# AE822FA0E5597BS0_CM55_HP_View register map
Vendor: Alif Semiconductor; Series: E8; File version: 1.0
CPU: CM55 r1p0, selectable endian, MPU, FPU, double-precision FPU, DSP, VTOR, 8 interrupt priority bits, 1 SAU regions
Registers are 32-bit, read-write, reset 0x0 unless marked. A register's access mark holds for its fields unless they carry their own. Offsets are from the block's base; [hi:lo] are bit positions; {n}, {i} and the like mark numbered series; 'fields as' and 'values as' point back to an identical list.

## OSPI0
Base 0x83000000
Same registers: OSPI1 0x83002000
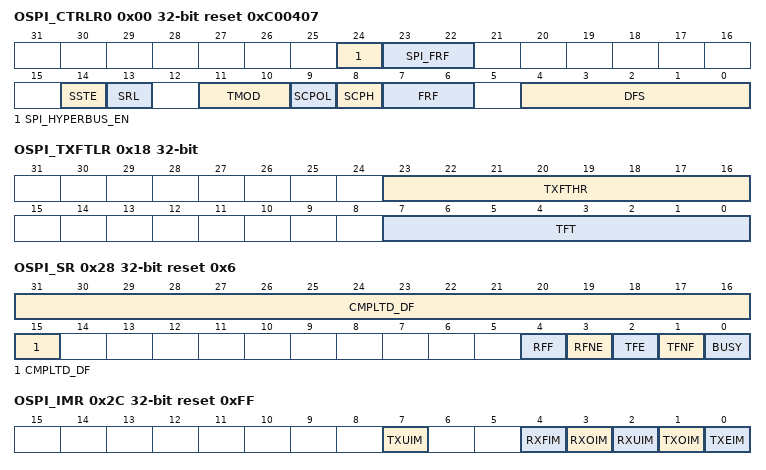
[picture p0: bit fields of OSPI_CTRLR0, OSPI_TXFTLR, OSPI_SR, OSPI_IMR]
0x00 OSPI_CTRLR0 reset 0xC00407 — OSPI Control Register 0
  [24] SPI_HYPERBUS_EN — SPI HyperBus Frame Format Enable. Selects if data frame format for Transmitting/Receiving data is in HyperBus mode.
    0=Disable HyperBus format; 1=Enable HyperBus format
  [23:22] SPI_FRF — SPI Frame Format Selects data frame format for Transmitting/Receiving the data.
    0=Standard SPI format; 1=Dual SPI format; 2=Quad SPI format; 3=Octal SPI format
  [14] SSTE — Slave Select Toggle Enable. While operating in SPI mode with SCPH set to 0, this bit controls the behavior of the slave select line between data frames.
    0=The slave select line will stay low and OSPI_SCLK will run continuously for the duration of the transfer; 1=The slave select line will toggle between consecutive data frames, with the serial clock (OSPI_SCLK) being held to its default value while the slave select line is high
  [13] SRL — Shift Register Loop. Used for testing purposes only. When internally active, connects the transmit shift register output to the receive shift register input.
    0=Normal mode operation; 1=Test mode operation
  [11:10] TMOD — Transfer Mode. Selects the mode of transfer for serial communication. This field does not affect the transfer duplicity. Only indicates whether the receive or transmit data are valid. In Transmit Only mode, data received from the external device is not valid and is not stored in the receive FIFO memory; it is overwritten on the next transfer. In Receive Only mode, transmitted data are not valid. After the first write to the transmit FIFO, the same word is retransmitted for the duration of the transfer. In transmit-and-receive mode, both transmit and receive data are valid. The transfer continues until the transmit FIFO is empty. Data received from the external device are stored into the receive FIFO memory, where it can be accessed by the host processor.
    0=Transmit and Receive; Not Applicable in enhanced SPI operating mode; 1=Transmit Only mode; Or Write in enhanced SPI operating mode; 2=Receive Only mode; Or Read in enhanced SPI operating mode; 3=EEPROM Read mode; Not Applicable in enhanced SPI operating mode
  [9] SCPOL — Serial Clock Polarity. Used to select the polarity of the inactive serial clock, which is held inactive when the OSPI master is not actively transferring data on the serial bus.
    0=Inactive state of serial clock is low; 1=Inactive state of serial clock is high
  [8] SCPH — Serial Clock Phase. The serial clock phase selects the relationship of the serial clock with the slave select signal. When SCPH = 0, data are captured on the first edge of the serial clock. When SCPH = 1, the serial clock starts toggling one cycle after the slave select line is activated, and data are captured on the second edge of the serial clock.
    0=Serial clock toggles in middle of first bit; 1=Serial clock toggles at start of first bit
  [7:6] FRF — Frame Format. Selects which serial protocol transfers the data.
    0=Motorola SPI Frame Format
  [4:0] DFS — Data Frame Size. Selects the data frame length. When the data frame size is programmed to be less than 32-bits, the receive data is automatically right-justified by the receive logic, with the upper bits of the receive FIFO zero-padded. Software must right-justify transmit data before writing into the transmit FIFO. The transmit logic ignores the upper unused bits when transmitting the data. Note: The DFS value must be multiple of 2 if SPI_FRF = 0x1, multiple of 4 if SPI_FRF = 0x2, and multiple of 8 if SPI_FRF = 0x3.
    {v}={v+1:02}-bit serial data transfer (v=3..31)
0x04 OSPI_CTRLR1 — OSPI Control Register 1
  [15:0] NDF — Number of Data Frames. When OSPI_CTRLR0[TMOD] = 0x2 or 0x3, this bit field sets the number of data frames to be continuously received by the OSPI. The OSPI continues to receive serial data until the number of data frames received is equal to this register value plus 1, which enables to receive up to 256KB of data in a continuous transfer. When OSPI_CTRLR0[TMOD] = 0x1, this bit field sets the number of data frames to be continuously transmitted by OSPI. If the Transmit FIFO goes empty in-between, OSPI masks the serial clock (OSPI_SCLK) and waits for rest of the data until the programmed amount of frames are transferred successfully.
0x08 OSPI_ENR — OSPI Enable Register
  [0] OSPI_EN — OSPI Enable. Enables or disables all OSPI operations. When disabled, all serial transfers are halted immediately. Transmit and receive FIFO buffers are cleared when the device is disabled. It is impossible to program some of the OSPI control registers when enabled.
    0=Disables OSPI; 1=Enables OSPI
0x10 OSPI_SER — OSPI Slave Enable Register
  [1:0] SER — Slave Select Enable Flag. Each bit of this bit field corresponds to the slave select line from the OSPI master. When a bit in this bit field is set (0x1), the slave select line from the master is activated when a serial transfer begins. It should be noted that setting or clearing bits in this bit field have no effect on the corresponding slave select output until a transfer is started. Before beginning a transfer, the respective bit in this bit field should be enabled depending which slave select line is desired.
    0=Not selected; 1=Selected
0x14 OSPI_BAUDR reset 0x2 — OSPI Baud Rate Select Register
  [15:1] SCKDV — OSPI Clock Divider. This field contains the MSB 15 bits of the 16-bit SPI_CLK divider value. The LSB for this bit field is always set to 0 and is unaffected by a write operation, which ensures the divider is always set to an even value. If this field is set to all 0s, the serial output clock (OSPI_SCLK) is disabled. The frequency of the OSPI_SCLK is derived from the following equation: FOSPI_SCLK = FOSPI_CLK/BAUDR Where BAUDR is any even value between 2 and 65534, and BAUDR = SCKDV x 2. For example, for FOSPI_CLK = 3.6864 MHz and SCKDV = 1b'1: BAUDR = 2 and FOSPI_SCLK = 3.6864/2 = 1.8432 MHz
0x18 OSPI_TXFTLR — OSPI Transmit FIFO Threshold Level Register
  [23:16] TXFTHR — Transfer Start FIFO Level. Used to control the level of entries in transmit FIFO above which transfer will start on serial line. This bit field is used to ensure that sufficient data is present in transmit FIFO before starting a write operation on serial line.
  [7:0] TFT — Transmit FIFO Threshold. Controls the level of entries (or below) at which the transmit FIFO controller triggers an interrupt. The FIFO depth is 256. If the value in this bit field is greater than or equal to the depth of the FIFO, this bit field is not written and retains its current value. When the number of transmit FIFO entries is less than or equal to this value, the transmit FIFO empty interrupt is triggered.
0x1C OSPI_RXFTLR — OSPI Receive FIFO Threshold Level Register
  [7:0] RFT — Receive FIFO Threshold. Controls the level of entries (or above) at which the receive FIFO controller triggers an interrupt. The FIFO depth is 256. If the value in this bit field is greater than the depth of the FIFO, this bit field is not written and retains its current value. When the number of receive FIFO entries is greater than or equal to this value + 1, the receive FIFO full interrupt is triggered.
0x20 OSPI_TXFLR ro — OSPI Transmit FIFO Level Register
  [8:0] TXTFL — Transmit FIFO Level. Contains the number of valid data entries in the transmit FIFO.
0x24 OSPI_RXFLR ro — OSPI Receive FIFO Level Register
  [8:0] RXTFL — Receive FIFO Level. Contains the number of valid data entries in the receive FIFO.
0x28 OSPI_SR ro reset 0x6 — OSPI Status Register
  [31:15] CMPLTD_DF — Completed Data Frames. This bit field indicates total data frames transferred in the previous internal DMA transfer.
  [4] RFF — Receive FIFO Full. When the receive FIFO is completely full, this bit is set. When the receive FIFO contains one or more empty location, this bit is cleared.
    0=Receive FIFO is not full; 1=Receive FIFO is full
  [3] RFNE — Receive FIFO Not Empty. Set when the receive FIFO contains one or more entries and is cleared when the receive FIFO is empty. This bit can be polled by software to completely empty the receive FIFO.
    0=Receive FIFO is empty; 1=Receive FIFO is not empty
  [2] TFE — Transmit FIFO Empty. When the transmit FIFO is completely empty, this bit is set. When the transmit FIFO contains one or more valid entries, this bit is cleared. This bit field does not request an interrupt.
    0=Transmit FIFO is not empty; 1=Transmit FIFO is empty
  [1] TFNF — Transmit FIFO Not Full. Set when the transmit FIFO contains one or more empty locations, and is cleared when the FIFO is full.
    0=Transmit FIFO is full; 1=Transmit FIFO is not full
  [0] BUSY — OSPI Busy Flag. When set, indicates that a serial transfer is in progress; when cleared indicates that the OSPI is idle or disabled.
    0=OSPI is idle or disabled; 1=OSPI is actively transferring data
0x2C OSPI_IMR reset 0xFF — OSPI Interrupt Mask Register
  [7] TXUIM — Transmit FIFO Underflow Interrupt Mask
    0=Transmit FIFO Underflow interrupt is masked; 1=Transmit FIFO Underflow interrupt is not masked
  [4] RXFIM — Receive FIFO Full Interrupt Mask
    0=Receive FIFO Full interrupt is masked; 1=Receive FIFO Full interrupt is not masked
  [3] RXOIM — Receive FIFO Overflow Interrupt Mask
    0=Receive FIFO Overflow interrupt is masked; 1=Receive FIFO Overflow interrupt is not masked
  [2] RXUIM — Receive FIFO Underflow Interrupt Mask
    0=Receive FIFO Underflow interrupt is masked; 1=Receive FIFO Underflow interrupt is not masked
  [1] TXOIM — Transmit FIFO Overflow Interrupt Mask
    0=Transmit FIFO Overflow interrupt is masked; 1=Transmit FIFO Overflow interrupt is not masked
  [0] TXEIM — Transmit FIFO Empty Interrupt Mask
    0=Transmit FIFO Empty interrupt is masked; 1=Transmit FIFO Empty interrupt is not masked
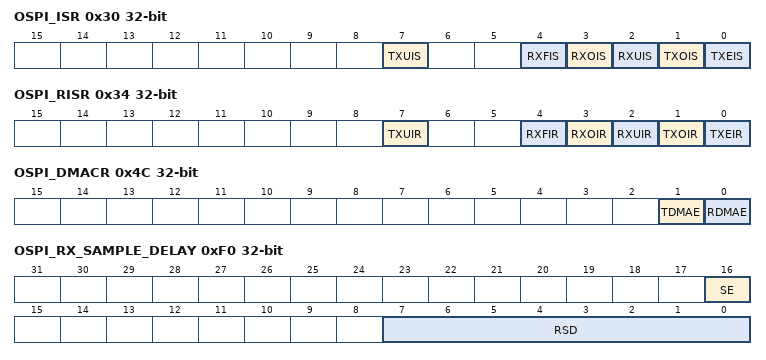
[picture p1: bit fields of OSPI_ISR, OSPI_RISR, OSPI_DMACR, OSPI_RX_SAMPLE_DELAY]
0x30 OSPI_ISR ro — OSPI Interrupt Status Register
  [7] TXUIS — Transmit FIFO Underflow Interrupt Status
    0=Transmit FIFO Underflow interrupt is not active after masking; 1=Transmit FIFO Underflow interrupt is active after masking
  [4] RXFIS — Receive FIFO Full Interrupt Status.
    0=Receive FIFO Full interrupt is not active after masking; 1=Receive FIFO Full interrupt is active after masking
  [3] RXOIS — Receive FIFO Overflow Interrupt Status.
    0=Receive FIFO Overflow interrupt is not active after masking; 1=Receive FIFO Overflow interrupt is active after masking
  [2] RXUIS — Receive FIFO Underflow Interrupt Status.
    0=Receive FIFO Underflow interrupt is not active after masking; 1=Receive FIFO Underflow interrupt is active after masking
  [1] TXOIS — Transmit FIFO Overflow Interrupt Status.
    0=Transmit FIFO Overflow interrupt is not active after masking; 1=Transmit FIFO Overflow interrupt is active after masking
  [0] TXEIS — Transmit FIFO Empty Interrupt Status.
    0=Transmit FIFO Empty interrupt is not active after masking; 1=Transmit FIFO Empty interrupt is active after masking
0x34 OSPI_RISR ro — OSPI Raw Interrupt Status Register
  [7] TXUIR — Transmit FIFO Underflow Interrupt Raw Status
    0=Transmit FIFO Underflow interrupt is not active prior masking; 1=Transmit FIFO Underflow interrupt is active prior to masking
  [4] RXFIR — Receive FIFO Full Raw Interrupt Status.
    0=Receive FIFO Full interrupt is not active prior masking; 1=Receive FIFO Full interrupt is active prior to masking
  [3] RXOIR — Receive FIFO Overflow Raw Interrupt Status.
    0=Receive FIFO Overflow interrupt is not active prior masking; 1=Receive FIFO Overflow interrupt is active prior to masking
  [2] RXUIR — Receive FIFO Underflow Raw Interrupt Status.
    0=Receive FIFO Underflow interrupt is not active prior masking; 1=Receive FIFO Underflow interrupt is active prior to masking
  [1] TXOIR — Transmit FIFO Overflow Raw Interrupt Status.
    0=Transmit FIFO Overflow interrupt is not active prior masking; 1=Transmit FIFO Overflow interrupt is active prior to masking
  [0] TXEIR — Transmit FIFO Empty Raw Interrupt Status.
    0=Transmit FIFO Empty interrupt is not active prior masking; 1=Transmit FIFO Empty interrupt is active prior to masking
0x38 OSPI_TXEICR ro — OSPI Transmit FIFO Error Interrupt Clear Register
  [0] TXEICR — Clear Transmit FIFO Overflow/Underflow Interrupt. This bit reflects the status of the interrupt. A read from this bit clears the Transmit FIFO Overflow/Underflow interrupt; writing has no effect.
0x3C OSPI_RXOICR ro — OSPI Receive FIFO Overflow Interrupt Clear Register
  [0] RXOICR — Clear Receive FIFO Overflow Interrupt. This bit reflects the status of the interrupt. A read from this bit clears the Receive FIFO Overflow interrupt; writing has no effect.
0x40 OSPI_RXUICR ro — OSPI Receive FIFO Underflow Interrupt Clear Register
  [0] RXUICR — Clear Receive FIFO Underflow Interrupt. This bit reflects the status of the interrupt. A read from this bit clears the Receive FIFO Underflow interrupt; writing has no effect.
0x48 OSPI_ICR ro — OSPI Interrupt Clear Register
  [0] ICR — Clear Interrupts. This bit is set if any of the interrupts below are active. A read clears the Transmit FIFO Underflow, Transmit FIFO Overflow, Receive FIFO Underflow, and Receive FIFO Overflow interrupts. Writing to this bit has no effect.
0x4C OSPI_DMACR — OSPI DMA Control Register
  [1] TDMAE — Transmit DMA Enable. This bit enables/disables the transmit FIFO DMA channel.
    0=Transmit DMA disabled; 1=Transmit DMA enabled
  [0] RDMAE — Receive DMA Enable. This bit enables/disables the receive FIFO DMA channel.
    0=Receive DMA disabled; 1=Receive DMA enabled
0x50 OSPI_DMATDLR — OSPI DMA Transmit Data Level Register
  [7:0] DMATDL — Transmit Data Level. This bit field controls the level at which a DMA request is made by the transmit logic. It is equal to the Watermark Level; that is, the OSPI_DMA_TX_REQ signal is generated when the number of valid data entries in the transmit FIFO is equal to or below this field value, and OSPI_DMACR[TDMAE] = 1.
0x54 OSPI_DMARDLR — OSPI DMA Receive Data Level Register
  [7:0] DMARDL — Receive Data Level. This bit field controls the level at which a DMA request is made by the receive logic. The Watermark Level is equal to OSPI_DMARDLR[DMARDL] + 1; that is, OSPI_DMA_RX_REQ is generated when the number of valid data entries in the receive FIFO is equal to or above this field value + 1, and OSPI_DMACR[RDMAE] = 1.
0x58 OSPI_IDR ro reset 0xC7C5C7C5 — Identification Register
  [31:0] IDCODE — Identification code
0x5C OSPI_VERSION_ID ro reset 0x3230312A — Version ID Register
  [31:0] OSPI_COMP_VERSION — Component version
{0x60+4i} OSPI_DR[{i}] (i=0..35) — OSPI Data Register (n)
  [31:0] DR — Data Register (n). When writing to this register, the data must be right-justified. Read data are automatically right-justified. Read = Receive FIFO buffer Write = Transmit FIFO buffer
0xF0 OSPI_RX_SAMPLE_DELAY
  [16] SE — RXD Sampling Edge. This bit is used to decide the sampling edge for RXD signal with OSPI_CLK. Then this bit is set to 1 then negative edge of OSPI_CLK will be used to sample the incoming data, otherwise positive edge will be used for sampling.
  [7:0] RSD — RXD Sample Delay. This bit field is used to delay the sample of the RXD input port. Each value represents a single OSPI_CLK delay on the sample of RXD. Note: If this bit is programmed with a value that exceeds the depth of the internal shift registers (internal shift register depth = 8) zero delay will be applied to the RXD sample.
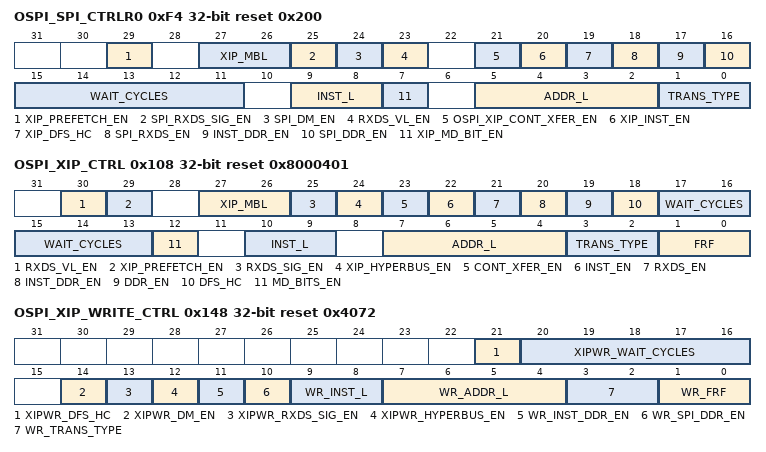
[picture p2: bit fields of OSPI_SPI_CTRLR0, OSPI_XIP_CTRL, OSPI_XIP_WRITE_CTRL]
0xF4 OSPI_SPI_CTRLR0 reset 0x200 — OSPI SPI Control Register 0
  [29] XIP_PREFETCH_EN ro — Enables XIP Pre-fetch functionality in OSPI. Once enabled OSPI will pre-fetch data frames from next contiguous location, to reduce the latency for the upcoming contiguous transfer. If the next XIP request is not contiguous then pre-fetched bits will be discarded.
  [27:26] XIP_MBL ro — XIP Mode Bits Length. Sets the length of Mode bits in XIP mode of operation. These bits are valid only when OSPI_SPI_CTRLR0[XIP_MD_BIT_EN] is set to 1.
    0=Mode bits length equal to 2; 1=Mode bits length equal to 4; 2=Mode bits length equal to 8; 3=Mode bits length equal to 16
  [25] SPI_RXDS_SIG_EN — Enable RXDS Signaling during address and command phase of HyperBus transfer. This bit enables RXDS signaling by HyperBus slave devices during Command-Address (CA) phase. If the RXDS signal is set to 1 during the CA phase of transfer, OSPI transmits [2 x OSPI_SPI_CTRLR0[WAIT_CYCLES]) - 1] wait cycles after the address phase is complete.
  [24] SPI_DM_EN — SPI Data Mask Enable bit. When this bit is enabled, the TXD_DM signal is used to mask the data on the TXD data line.
  [23] RXDS_VL_EN — RXDS Variable Latency Enable bit. When this bit is set OSPI waits for all the data to be sampled before stopping the OSPI_SCLK clock. This enables the support for devices which support variable latencies during RXDS transfers.
  [21] OSPI_XIP_CONT_XFER_EN ro — Enable Continuous Transfer in XIP mode. If this bit is set to 1 then continuous transfer mode in XIP is enabled, in this mode OSPI keeps the slave selected until a non-XIP transfer is detected on the AHB interface.
  [20] XIP_INST_EN ro — XIP Instruction Enable bit. If this bit is set to 1 then XIP transfers also have an instruction phase. The instruction opcodes can be chosen from OSPI_XIP_INCR_INST or OSPI_XIP_WRAP_INST registers bases on AHB transfer type.
  [19] XIP_DFS_HC ro — Fix DFS for XIP transfers. If this bit is set to 1 then data frame size for XIP transfers is fixed to the programmed value in OSPI_CTRLR0[DFS] bit field. The number of data frames to fetch is determined by transfer size and burst type signals. If this bit is set to 0 then data frame size and number of data frames to fetch are both determined by transfer size and burst type signals.
  [18] SPI_RXDS_EN — Read Data Strobe Enable bit. Once this bit is set to 1 OSPI uses Read data strobe (RXDS) to capture read data in DDR mode.
  [17] INST_DDR_EN — Instruction DDR Enable bit. This bit enables Dual Data-Rate transfer for instruction phase.
  [16] SPI_DDR_EN — SPI DDR Enable bit. This bit enables Dual Data-Rate transfers in Enhanced SPI frame formats of SPI.
  [15:11] WAIT_CYCLES — Wait cycles in SPI mode between control frames transmission and data transmission/reception. Specified as number of SPI clock cycles. Note: If wait cycles during the write transfer are not needed this field can be set to 0x0.
  [9:8] INST_L — Enhanced SPI mode instruction length in bits. Note: For enhanced SPI modes, INST_L and ADDR_L cannot be both programmed to 0x0 at the same time.
    0=No Instruction; 1=4-bit instruction length; 2=8-bit instruction length; 3=16-bit instruction length
  [7] XIP_MD_BIT_EN ro — Mode bits enable in XIP mode. If this bit is set to 0x1, then in XIP mode of operation OSPI inserts Mode bits after the address phase. These bits are set in register OSPI_XIP_MODE_BITS register. The length of Mode bits defaults to 8-bits.
  [5:2] ADDR_L — This bit defines Length of Address to be transmitted. Only after this much bits are programmed in to the FIFO the transfer can begin. Note: For enhanced SPI modes, INST_L and ADDR_L cannot be both programmed to 0x0 at the same time.
    0=No address; 1=4-bit address length; 2=8-bit address length; 3=12-bit address length; 4=16-bit address length; 5=20-bit address length; 6=24-bit address length; 7=28-bit address length; 8=32-bit address length; 9=36-bit address length; 10=40-bit address length; 11=44-bit address length; 12=48-bit address length; 13=52-bit address length; 14=56-bit address length; 15=60-bit address length
  [1:0] TRANS_TYPE — Address and Instruction Transfer format. Selects whether OSPI will transmit instruction/address either in Standard SPI mode or the SPI mode selected in the OSPI_CTRLR0[SPI_FRF] bit field.
    0=Instruction and Address will be sent in Standard SPI Mode; 1=Instruction will be sent in Standard SPI Mode and Address will be sent in the mode specified by the OSPI_CTRLR0[SPI_FRF] bit field; 2=Both Instruction and Address will be sent in the mode specified by OSPI_CTRLR0[SPI_FRF] bit field; 3=Dual Octal mode. The address and instruction are transferred in octal mode and data is transferred on 16 data lines.
0xF8 OSPI_DDR_DRIVE_EDGE — OSPI Transmit Drive Edge Register
  [7:0] TDE — TXD Drive Edge register which decided the driving edge of transmit data. The maximum value of this bit field is equal to [(BAUDR/2) - 1].
0xFC OSPI_XIP_MODE_BITS
  [15:0] XIP_MD_BITS — XIP Mode bits to be sent after address phase of XIP transfer.
0x100 OSPI_XIP_INCR_INST — OSPI XIP INCR Transfer Opcode Register
  [15:0] INCR_INST — XIP INCR transfer opcode. When OSPI_SPI_CTRLR0[XIP_INST_EN] bit is set to 1, OSPI sends instruction for all XIP transfers, this register field stores the instruction opcode to be sent when an INCR type transfer is requested on AHB bus. The number of bits to be send in instruction phase is determined by the OSPI_SPI_CTRLR0[INST_L] bit field.
0x104 OSPI_XIP_WRAP_INST — OSPI XIP WRAP Transfer Opcode Register
  [15:0] WRAP_INST — XIP WRAP transfer opcode. When OSPI_SPI_CTRLR0[XIP_INST_EN] bit is set to 1, OSPI sends instruction for all XIP transfers, this register field stores the instruction opcode to be sent when an WRAP type transfer is requested on AHB bus. The number of bits to be send in instruction phase is determined by the OSPI_SPI_CTRLR0[INST_L] bit field.
0x108 OSPI_XIP_CTRL reset 0x8000401 — OSPI XIP Control Register
  [30] RXDS_VL_EN — RXDS Variable Latency Enable. When this bit is set OSPI waits for all the data to be sampled before stopping the OSPI_SCLK clock. This enables the support for devices which support variable latencies during RXDS transfers.
  [29] XIP_PREFETCH_EN — Enables XIP Pre-fetch functionality in OSPI. Once enabled OSPI will pre-fetch data frames from next contiguous location, to reduce the latency for the upcoming contiguous transfer. If the next XIP request is not contiguous then pre-fetched bits will be discarded.
  [27:26] XIP_MBL — XIP Mode Bits Length. Sets the length of Mode bits in XIP mode of operation. These bits are valid only when OSPI_XIP_CTRL[XIP_MD_BIT_EN] is set to 1.
    values as OSPI_SPI_CTRLR0.XIP_MBL
  [25] RXDS_SIG_EN — Enable RXDS Signaling during address and command phase of HyperBus transfer. This bit enables RXDS signaling by HyperBus slave devices during Command-Address (CA) phase. If the RXDS signal is set to 1 during the CA phase of transfer, OSPI transmits [2 x OSPI_SPI_CTRLR0[WAIT_CYCLES]) - 1] wait cycles after the address phase is complete.
  [24] XIP_HYPERBUS_EN — SPI Hyperbus Frame format enable for XIP transfers. Selects if data frame format for XIP transfers is in HyperBus mode.
  [23] CONT_XFER_EN — Enable Continuous Transfer in XIP mode. If this bit is set to 1 then continuous transfer mode in XIP will be enabled, in this mode OSPI will keep slave selected until a non-XIP transfer is detected on the AHB interface.
  [22] INST_EN — XIP Instruction Enable bit. If this bit is set to 1 then XIP transfers will also have instruction phase. The instruction opcodes can be chosen from OSPI_XIP_INCR_INST or OSPI_XIP_WRAP_INST registers bases on AHB transfer type.
  [21] RXDS_EN — Read Data Strobe Enable bit. Once this bit is set to 1, OSPI will use Read data strobe (RXDS) to capture read data in DDR mode.
  [20] INST_DDR_EN — Instruction DDR Enable bit. This bit enables Dual Data-Rate transfer for instruction phase
  [19] DDR_EN — SPI DDR Enable bit. This bit enables Dual Data-Rate transfers in Enhanced SPI frame formats of SPI.
  [18] DFS_HC — Fix DFS for XIP transfers. If this bit is set to 1 then data frame size for XIP transfers is fixed to the programmed value in OSPI_CTRLR0[DFS] bit field. The number of data frames to fetch is determined by transfer size and burst type signals. If this bit is set to 0 then data frame size and number of data frames to fetch are both determined by transfer size and burst type signals.
  [17:13] WAIT_CYCLES — Wait cycles in SPI mode between control frames transmission and data transmission/reception. Specified as number of SPI clock cycles.
  [12] MD_BITS_EN — Mode bits enable in XIP mode. If this bit is set to 1, then in XIP mode of operation OSPI will insert Mode bits after the address phase. These bits are set in register OSPI_XIP_MODE_BITS register. The length of Mode bits defaults to 8-bits.
  [10:9] INST_L — Enhanced SPI mode instruction length in bits.
    values as OSPI_SPI_CTRLR0.INST_L
  [7:4] ADDR_L — This bit defines Length of Address to be transmitted. Only after this much bits are programmed in to the FIFO the transfer can begin.
    values as OSPI_SPI_CTRLR0.ADDR_L
  [3:2] TRANS_TYPE — Address and Instruction Transfer format. Selects whether OSPI will transmit instruction/address either in Standard SPI mode or the SPI mode selected in the OSPI_XIP_CTRL[FRF] bit field.
    0=Instruction and Address will be sent in Standard SPI Mode; 1=Instruction will be sent in Standard SPI Mode and Address will be sent in the mode specified by OSPI_XIP_CTRL[FRF] bit field; 2=Both Instruction and Address will be sent in the mode specified by OSPI_XIP_CTRL[FRF] bit field; 3=Dual Octal mode. The address and instruction are transferred in octal mode and data is transferred on 16 data lines.
  [1:0] FRF — SPI Frame Format Selects data frame format for Receiving the data.
    0=Standard SPI Format; 1=Dual SPI format; 2=Quad SPI format; 3=Octal SPI format
0x114 OSPI_XIP_CNT_TIME_OUT — OSPI XIP Timeout Register for Continuous Transfers
  [7:0] XTOC — XIP Timeout Counter XIP timeout value in terms of HCLK. Once slave is selected in continuous XIP mode this counter will be used to de-select the slave if there is no request for the time specified in the counter.
0x118 OSPI_SPI_CTRLR1 — OSPI SPI Control Register 1
  [19:16] CS_MIN_HIGH — Chip-Select Minimum High Period. This field is used to set the minimum time period (in terms of OSPI_CLK) between two back to back SPI operations.
0x140 OSPI_XIP_WRITE_INCR_INST — OSPI XIP Write INCR Transfer Opcode Register
  [15:0] INCR_WRITE_INST — XIP Write INCR transfer opcode. When OSPI_XIP_WRITE_CTRL[INST_L] is not equal to 0x0, OSPI sends instruction for all XIP write transfers. This field stores the instruction op-code to be sent when an INCR type XIP Write transfer is requested on AHB bus. The number of bits to be send in instruction phase is determined by the OSPI_XIP_WRITE_CTRL[INST_L] field.
0x144 OSPI_XIP_WRITE_WRAP_INST — OSPI XIP Write WRAP Transfer Opcode Register
  [15:0] WRAP_WRITE_INST — XIP Write WRAP transfer opcode. When OSPI_XIP_WRITE_CTRL[INST_L] is not equal to 0x0, OSPI sends instruction for all XIP write transfers. This field stores the instruction op-code to be sent when a WRAP type XIP Write transfer is requested on AHB bus. The number of bits to be send in instruction phase is determined by the OSPI_XIP_WRITE_CTRL[INST_L] field.
0x148 OSPI_XIP_WRITE_CTRL reset 0x4072 — OSPI XIP Write Control Register
  [21] XIPWR_DFS_HC — Fix Data Frame Size (DFS) for XIP transfers. If this bit is set to 0x1, then DFS for XIP transfers will be fixed to the programmed value in OSPI_CTRLR0[DFS]. If this bit is set to 0x0, then data frame size will be determined by HSIZE signal.
  [20:16] XIPWR_WAIT_CYCLES — Wait cycles in SPI mode between control frames transmission and data transmission. Specified as number of SPI clock cycles.
  [14] XIPWR_DM_EN — SPI Data Mask Enable bit. When this bit is enabled, the TXD_DM signal is used to mask the data on the TXD data line.
  [13] XIPWR_RXDS_SIG_EN — Enable RXDS signaling during address and command phase of Hyperbus transfer. This bit enables RXDS signaling by Hyperbus slave devices during Command-Address (CA) phase. If the RXDS signal is set to 1 during the CA phase of transfer, OSPI transmits (2 x OSPI_XIP_WRITE_CTRL[WAIT_CYCLES] - 1) wait cycles after the address phase is complete.
  [12] XIPWR_HYPERBUS_EN — SPI Hyperbus Frame format enable for XIP Write transfers. Selects if data frame format for XIP Write transfers is in Hyperbus mode.
  [11] WR_INST_DDR_EN — Instruction DDR Enable bit. This will enable Dual Data-Rate transfer for Instruction phase.
  [10] WR_SPI_DDR_EN — SPI DDR Enable bit. This will enable Dual Data-Rate transfers in Enhanced SPI frame formats of SPI.
  [9:8] WR_INST_L — Enhanced SPI mode instruction length in bits.
    0=No Instruction; 1=4-bit Instruction length; 2=8-bit Instruction length; 3=16-bit Instruction length
  [7:4] WR_ADDR_L — This bit defines Length of Address to be transmitted. Only after this much bits are programmed in to the FIFO the transfer can begin.
    1=4-bit Address length; 2=8-bit Address length; 3=12-bit Address length; 4=16-bit Address length; 5=20-bit Address length; 6=24-bit Address length; 7=28-bit Address length; 8=32-bit Address length
  [3:2] WR_TRANS_TYPE — Address and Instruction Transfer format. Selects whether OSPI will transmit instruction/address either in Standard SPI mode or the SPI mode selected in the OSPI_XIP_WRITE_CTRL[FRF] bit field.
    0=Instruction and Address will be sent in Standard SPI Mode; 1=Instruction will be sent in Standard SPI Mode and Address will be sent in the mode specified by OSPI_XIP_WRITE_CTRL[FRF] bit field; 2=Both Instruction and Address will be sent in the mode specified by OSPI_XIP_WRITE_CTRL[FRF] bit field; 3=Dual Octal mode. The address and instruction are transferred in octal mode and data is transferred on 16 data lines.
  [1:0] WR_FRF — SPI Frame Format Selects data frame format for Transmitting the data.
    0=Standard SPI Format; 1=Dual SPI Format; 2=Quad SPI Format; 3=Octal SPI Format
